# M461 register map
File version: 2.0.2.2
Registers are 32-bit, read-write, reset 0x0 unless marked. A register's access mark holds for its fields unless they carry their own. Offsets are from the block's base; [hi:lo] are bit positions; {n}, {i} and the like mark numbered series.

## CEC — Consumer Electronics Control (CEC)
Base 0x403E6000
0x00 EN — CEC Enable Register
  [0] CECEN
0x04 ADD — CEC Logical Address Register
  [15:0] CECADD
0x08 RESET wo — CEC Software Reset Register
  [0] CECRESET
0x0C REN (reset mask 0xFFFFFFFE) — CEC Receive Enable Register
  [0] CECREN
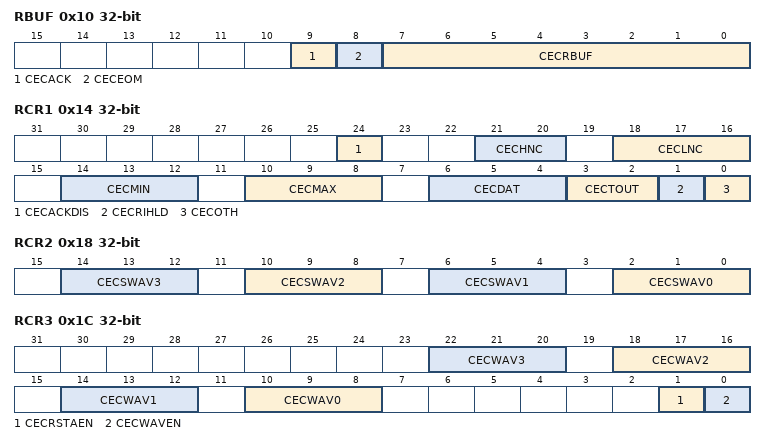
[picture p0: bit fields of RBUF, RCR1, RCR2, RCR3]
0x10 RBUF ro — CEC Receive Buffer Register
  [9] CECACK, [8] CECEOM, [7:0] CECRBUF
0x14 RCR1 — CEC Receive Control Register 1
  [24] CECACKDIS, [21:20] CECHNC, [18:16] CECLNC, [14:12] CECMIN, [10:8] CECMAX, [6:4] CECDAT, [3:2] CECTOUT, [1] CECRIHLD, [0] CECOTH
0x18 RCR2 — CEC Receive Control Register 2
  [4n+2:4n] CECSWAV{n} (n=0..3)
0x1C RCR3 — CEC Receive Control Register 3
  [4n+10:4n+8] CECWAV{n} (n=0..3), [1] CECRSTAEN, [0] CECWAVEN
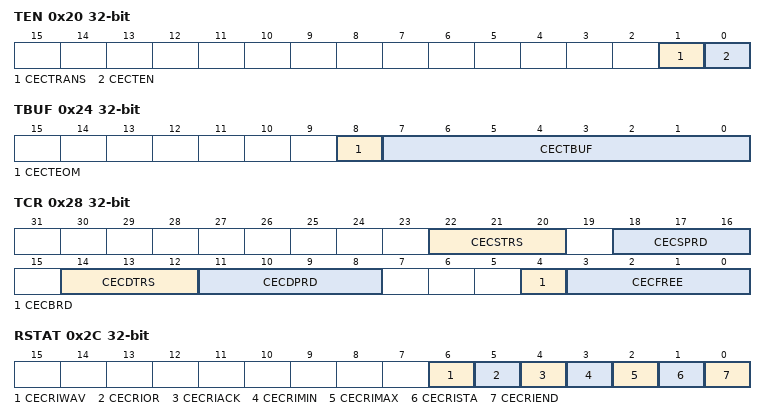
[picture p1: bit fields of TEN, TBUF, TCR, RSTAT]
0x20 TEN (reset mask 0xFFFFFFFE) — CEC Transmit Enable Register
  [1] CECTRANS ro, [0] CECTEN wo
0x24 TBUF — CEC Transmit Buffer Register
  [8] CECTEOM, [7:0] CECTBUF
0x28 TCR — CEC Transmit Control Register
  [22:20] CECSTRS, [18:16] CECSPRD, [14:12] CECDTRS, [11:8] CECDPRD, [4] CECBRD, [3:0] CECFREE
0x2C RSTAT ro — CEC Receive Interrupt Status Register
  [6] CECRIWAV, [5] CECRIOR, [4] CECRIACK, [3] CECRIMIN, [2] CECRIMAX, [1] CECRISTA, [0] CECRIEND
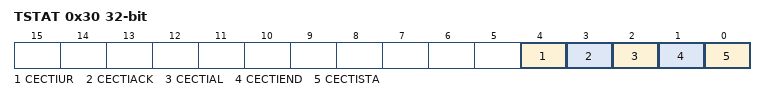
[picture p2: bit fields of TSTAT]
0x30 TSTAT ro — CEC Transmit Interrupt Status Register
  [4] CECTIUR, [3] CECTIACK, [2] CECTIAL, [1] CECTIEND, [0] CECTISTA
0x34 FSSEL — CEC sampling clock selection Register
  [0] CECCLK

## RMC — Remote Control Signal Preprocessor (RMC)
Base 0x403E7000
0x00 EN — RMC Enable Register
  [0] RMCEN
0x04 REN — RMC Receive Enable Register
  [0] RMCREN
0x08 RBUF1 ro — RMC Receive Data Buffer Register 1
  [31:0] RMCRBUF
0x0C RBUF2 ro — RMC Receive Data Buffer Register 2
  [31:0] RMCRBUF
0x10 RBUF3 ro — RMC Receive Data Buffer Register 3
  [7:0] RMCRBUF
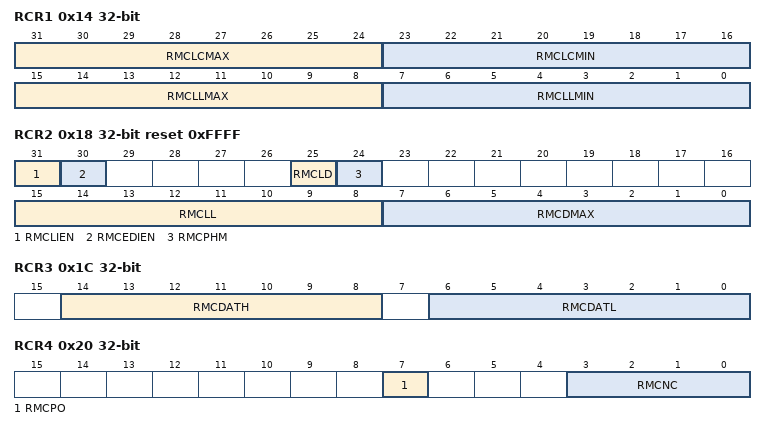
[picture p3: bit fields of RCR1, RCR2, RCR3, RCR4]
0x14 RCR1 — RMC Receive Control Register 1
  [31:24] RMCLCMAX, [23:16] RMCLCMIN, [15:8] RMCLLMAX, [7:0] RMCLLMIN
0x18 RCR2 reset 0xFFFF — RMC Receive Control Register 2
  [31] RMCLIEN, [30] RMCEDIEN, [25] RMCLD, [24] RMCPHM, [15:8] RMCLL, [7:0] RMCDMAX
0x1C RCR3 — RMC Receive Control Register 3
  [14:8] RMCDATH, [6:0] RMCDATL
0x20 RCR4 — RMC Receive Control Register 4
  [7] RMCPO, [3:0] RMCNC
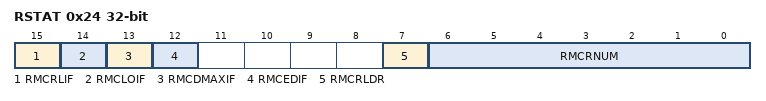
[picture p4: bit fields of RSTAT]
0x24 RSTAT ro — RMC Receive Status Register
  [15] RMCRLIF, [14] RMCLOIF, [13] RMCDMAXIF, [12] RMCEDIF, [7] RMCRLDR, [6:0] RMCRNUM
{0x24+4i} END{i} (i=1..3) — RMC Receive End Bit Number Register {i}
  [6:0] RMCEND{i}
0x34 FSSEL — RMC Frequency Selection Register
  [0] RMCCLK

## CG — Clock Generator (CG)
Base 0x403F3000
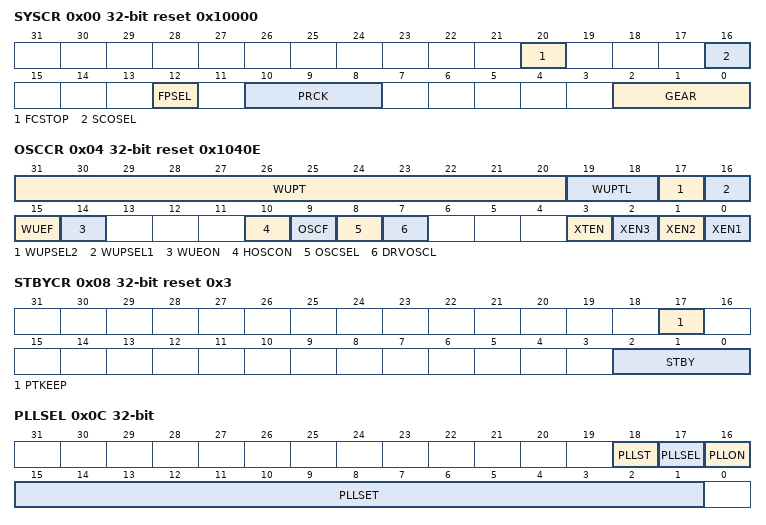
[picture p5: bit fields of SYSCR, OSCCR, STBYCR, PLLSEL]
0x00 SYSCR reset 0x10000 — System Control Register
  [20] FCSTOP, [16] SCOSEL, [12] FPSEL, [10:8] PRCK, [2:0] GEAR
0x04 OSCCR reset 0x1040E — Oscillation Control Register
  [31:20] WUPT, [19:18] WUPTL, [17] WUPSEL2, [16] WUPSEL1, [15] WUEF ro, [14] WUEON wo, [10] HOSCON, [9] OSCF ro, [8] OSCSEL, [7] DRVOSCL, [3] XTEN, [2] XEN3, [1] XEN2, [0] XEN1
0x08 STBYCR reset 0x3 — Standby Control Register
  [17] PTKEEP, [2:0] STBY
0x0C PLLSEL — PLL Selection Register
  [18] PLLST ro, [17] PLLSEL, [16] PLLON, [15:1] PLLSET
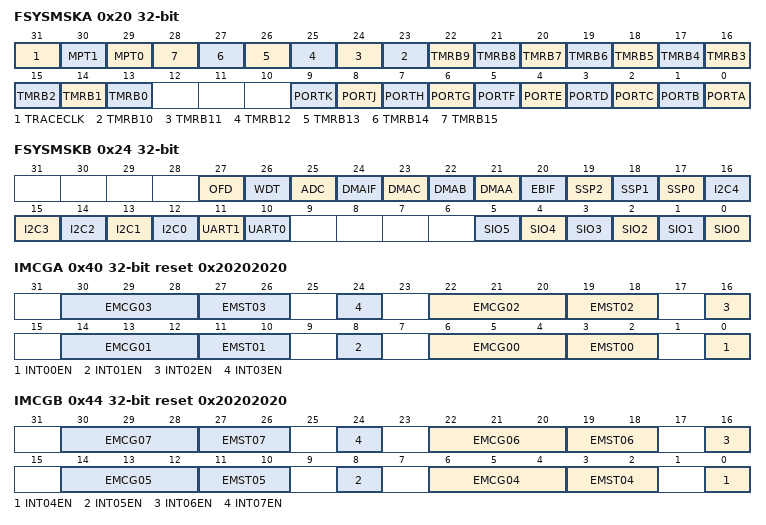
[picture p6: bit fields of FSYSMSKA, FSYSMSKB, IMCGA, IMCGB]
0x20 FSYSMSKA — fclk Supply Stop Register A
  [31] TRACECLK, [30] MPT1, [29] MPT0, [n+13] TMRB{n} (n=0..15), [9] PORTK, [8] PORTJ, [7] PORTH, [6] PORTG, [5] PORTF, [4] PORTE, [3] PORTD, [2] PORTC, [1] PORTB, [0] PORTA
0x24 FSYSMSKB — fclk Supply Stop Register B
  [27] OFD, [26] WDT, [25] ADC, [24] DMAIF, [23] DMAC, [22] DMAB, [21] DMAA, [20] EBIF, [19] SSP2, [18] SSP1, [17] SSP0, [n+12] I2C{n} (n=0..4), [11] UART1, [10] UART0, [n] SIO{n} (n=0..5)
0x3C PROTECT reset 0xC1
  [7:0] CGPROTECT
0x40 IMCGA reset 0x20202020 — CG Interrupt Mode Control Register A
  [8n+6:8n+4] EMCG{n:02} (n=0..3), [8n+3:8n+2] EMST{n:02} ro (n=0..3), [8n] INT{n:02}EN (n=0..3)
0x44 IMCGB reset 0x20202020 — CG Interrupt Mode Control Register B
  [8n-26:8n-28] EMCG{n:02} (n=4..7), [8n-29:8n-30] EMST{n:02} ro (n=4..7), [8n-32] INT{n:02}EN (n=4..7)
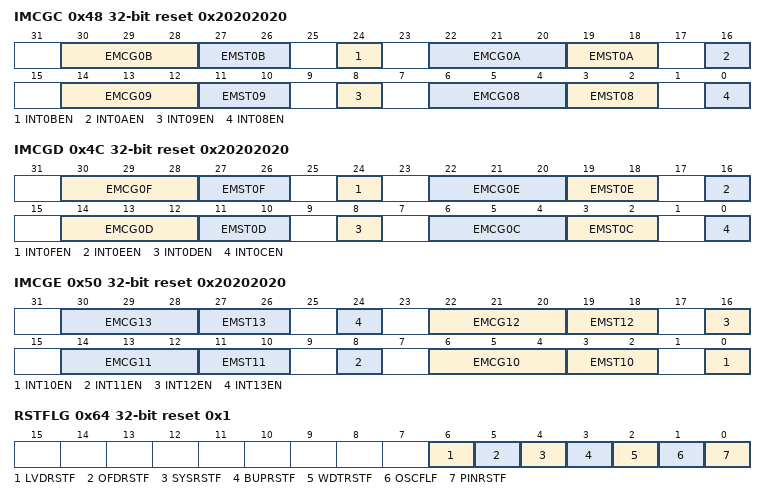
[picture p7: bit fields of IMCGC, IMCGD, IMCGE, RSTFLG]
0x48 IMCGC reset 0x20202020 — CG Interrupt Mode Control Register C
  [30:28] EMCG0B, [27:26] EMST0B ro, [24] INT0BEN, [22:20] EMCG0A, [19:18] EMST0A ro, [16] INT0AEN, [14:12] EMCG09, [11:10] EMST09 ro, [8] INT09EN, [6:4] EMCG08, [3:2] EMST08 ro, [0] INT08EN
0x4C IMCGD reset 0x20202020 — CG Interrupt Mode Control Register D
  [30:28] EMCG0F, [27:26] EMST0F ro, [24] INT0FEN, [22:20] EMCG0E, [19:18] EMST0E ro, [16] INT0EEN, [14:12] EMCG0D, [11:10] EMST0D ro, [8] INT0DEN, [6:4] EMCG0C, [3:2] EMST0C ro, [0] INT0CEN
0x50 IMCGE reset 0x20202020 — CG Interrupt Mode Control Register E
  [8n-74:8n-76] EMCG{n} (n=10..13), [8n-77:8n-78] EMST{n} ro (n=10..13), [8n-80] INT{n}EN (n=10..13)
0x60 ICRCG wo — CG Interrupt Request Clear Register
  [4:0] ICRCG
0x64 RSTFLG reset 0x1 (reset mask 0xFFFFFFFD) — Reset Flag Register
  [6] LVDRSTF, [5] OFDRSTF, [4] SYSRSTF, [3] BUPRSTF, [2] WDTRSTF, [1] OSCFLF ro, [0] PINRSTF
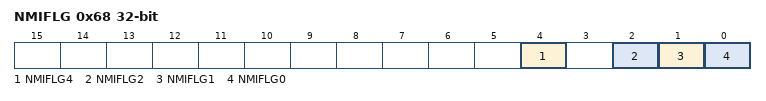
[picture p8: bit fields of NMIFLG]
0x68 NMIFLG ro — NMI Flag Register
  [4] NMIFLG4, [2] NMIFLG2, [1] NMIFLG1, [0] NMIFLG0

## LVD — Low voltage detecter
Base 0x403F4000
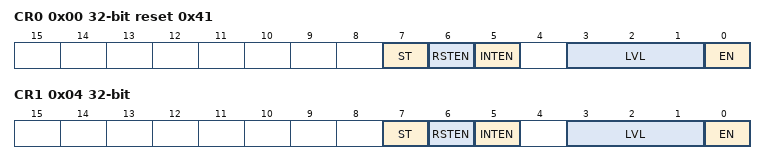
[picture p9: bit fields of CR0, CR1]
0x00 CR0 reset 0x41 — LVD detection control register 0
  [7] ST ro, [6] RSTEN, [5] INTEN, [3:1] LVL, [0] EN
0x04 CR1 — LVD detection control register 1
  [7] ST ro, [6] RSTEN, [5] INTEN, [3:1] LVL, [0] EN

## FC — Flash Control (FC)
Base 0x5DFF0000
0x10 SECBIT reset 0x1 — Security Bit Register
  [0] SECBIT
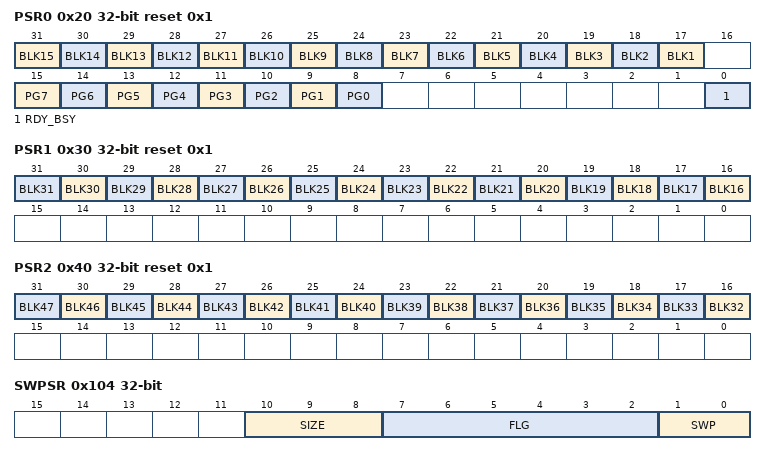
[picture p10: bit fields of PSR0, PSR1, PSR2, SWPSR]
0x20 PSR0 ro reset 0x1 (reset mask 0xFF) — Protect Status Register 0
  [n+16] BLK{n} (n=1..15), [n+8] PG{n} (n=0..7), [0] RDY_BSY
0x30 PSR1 ro reset 0x1 (reset mask 0xFFFF) — Protect Status Register 1
  [n] BLK{n} (n=16..31)
0x40 PSR2 ro reset 0x1 (reset mask 0xFFFF) — Protect Status Register 2
  [n-16] BLK{n} (n=32..47)
0x100 SR ro — Status Register
  [24] WEABORT
0x104 SWPSR ro — Swap Status Register
  [10:8] SIZE, [7:2] FLG, [1:0] SWP
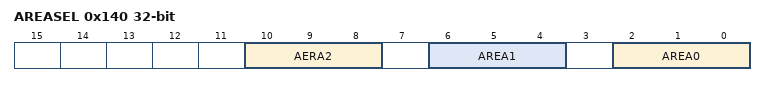
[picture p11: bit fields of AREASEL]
0x140 AREASEL — Area Selection Register
  [10:8] AERA2, [6:4] AREA1, [2:0] AREA0
0x148 CR — Control Register
  [2:0] WEABORT
0x14C STSCLR — Status Clear Register
  [2:0] WEABORT
0x150 WCLKCR — WCLK Configuration Register
  [4:0] DIV
0x154 PROGCR — Program Counter Configuration Register
  [1:0] CNT
0x158 ERASECR reset 0x6 — Erase Counter Configuration Register
  [3:0] CNT
